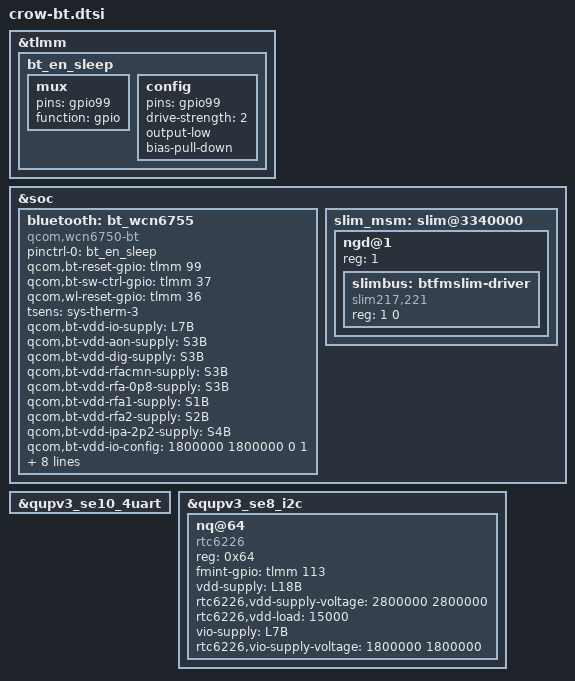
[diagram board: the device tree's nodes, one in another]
&tlmm {
	bt_en_sleep: bt_en_sleep {
		mux {
			pins = "gpio99";
			function = "gpio";
		};

		config {
			pins = "gpio99";
			drive-strength = <2>;
			output-low;
			bias-pull-down;
		};
	};
};


&soc {
    bluetooth: bt_wcn6755 {
	compatible = "qcom,wcn6750-bt";
	pinctrl-names = "default";
	pinctrl-0 = <&bt_en_sleep>;
	qcom,bt-reset-gpio = <&tlmm 99 0>; /* BT_EN */
	qcom,bt-sw-ctrl-gpio = <&tlmm 37 0>; /* SW_CTRL */
	qcom,wl-reset-gpio = <&tlmm 36 0>; /* WL_EN */
	tsens = "sys-therm-3";

	qcom,bt-vdd-io-supply = <&L7B>;  /* IO */
	qcom,bt-vdd-aon-supply = <&S3B>;
	qcom,bt-vdd-dig-supply = <&S3B>; /* BT_CX_MX */
	qcom,bt-vdd-rfacmn-supply = <&S3B>;
	qcom,bt-vdd-rfa-0p8-supply = <&S3B>;
	qcom,bt-vdd-rfa1-supply = <&S1B>; /*RFA 1p7*/
	qcom,bt-vdd-rfa2-supply = <&S2B>; /*RFA 1p2*/
	qcom,bt-vdd-ipa-2p2-supply = <&S4B>; /*IPA 2p2*/
	//qcom,bt-vdd-asd-supply = <&L11C>;

	/* max voltage are set to regulator max voltage supported */
	qcom,bt-vdd-io-config = <1800000 1800000 0 1>;
	qcom,bt-vdd-aon-config = <880000 1040000 0 1>;
	qcom,bt-vdd-dig-config = <880000 1040000 0 1>;
	qcom,bt-vdd-rfacmn-config  = <880000 1040000 0 1>;
	qcom,bt-vdd-rfa-0p8-config  = <880000 1040000 0 1>;
	qcom,bt-vdd-rfa1-config = <1856000 2040000 0 1>;
	qcom,bt-vdd-rfa2-config = <1256000 1408000 0 1>;
	qcom,bt-vdd-ipa-2p2-config = <2200000 2200000 0 1>;
	//qcom,bt-vdd-asd-config = <2800000 3544000 0 1>;
    };
	slim_msm: slim@3340000 {
		status =  "ok";
		ngd@1 {
			reg = <1>;
			#address-cells = <1>;
			#size-cells = <1>;

			//slimbus child nodes
			slimbus: btfmslim-driver {
				compatible = "slim217,221";
				reg = <1 0>;
			};
		};
	};
};

//uart instance
&qupv3_se10_4uart{
       status = "ok";
};

// FM changes
&qupv3_se8_i2c {
	status = "ok";
	nq@64 {
		compatible = "rtc6226";
		reg = <0x64>;
		fmint-gpio = <&tlmm 113 0>;
		vdd-supply = <&L18B>;
		rtc6226,vdd-supply-voltage = <2800000 2800000>;
		rtc6226,vdd-load = <15000>;
		vio-supply = <&L7B>;
		rtc6226,vio-supply-voltage = <1800000 1800000>;
	};
};
